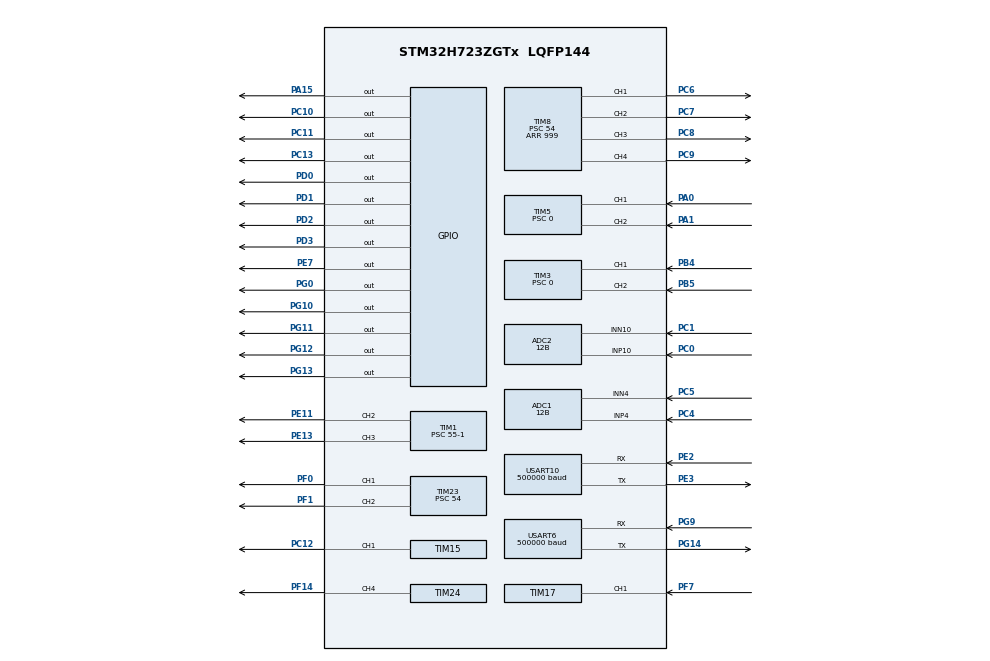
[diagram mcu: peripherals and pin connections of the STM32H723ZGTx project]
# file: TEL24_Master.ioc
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ADC1.Channel-0\#ChannelRegularConversion=ADC_CHANNEL_4
ADC1.ContinuousConvMode=ENABLE
ADC1.ConversionDataManagement=ADC_CONVERSIONDATA_DMA_CIRCULAR
ADC1.EOCSelection=ADC_EOC_SEQ_CONV
ADC1.NbrOfConversionFlag=1
ADC1.OffsetNumber-0\#ChannelRegularConversion=ADC_OFFSET_NONE
ADC1.OffsetSignedSaturation-0\#ChannelRegularConversion=DISABLE
ADC1.Overrun=ADC_OVR_DATA_OVERWRITTEN
ADC1.Rank-0\#ChannelRegularConversion=1
ADC1.Resolution=ADC_RESOLUTION_12B
ADC1.SamplingTime-0\#ChannelRegularConversion=ADC_SAMPLETIME_64CYCLES_5
ADC1.SingleDiff-0\#ChannelRegularConversion=ADC_DIFFERENTIAL_ENDED
ADC1.master=1
ADC2.Channel-0\#ChannelRegularConversion=ADC_CHANNEL_10
ADC2.ClockPrescaler=ADC_CLOCK_ASYNC_DIV1
ADC2.ContinuousConvMode=ENABLE
ADC2.ConversionDataManagement=ADC_CONVERSIONDATA_DMA_CIRCULAR
ADC2.DiscontinuousConvMode=DISABLE
ADC2.EOCSelection=ADC_EOC_SEQ_CONV
ADC2.ExternalTrigConv=ADC_SOFTWARE_START
ADC2.NbrOfConversion=1
ADC2.NbrOfConversionFlag=1
ADC2.Overrun=ADC_OVR_DATA_OVERWRITTEN
ADC2.Resolution=ADC_RESOLUTION_12B
ADC2.SamplingTime-0\#ChannelRegularConversion=ADC_SAMPLETIME_64CYCLES_5
ADC2.SingleDiff-0\#ChannelRegularConversion=ADC_DIFFERENTIAL_ENDED
Dma.ADC1.2.Direction=DMA_PERIPH_TO_MEMORY
Dma.ADC1.2.EventEnable=DISABLE
Dma.ADC1.2.FIFOMode=DMA_FIFOMODE_DISABLE
Dma.ADC1.2.Instance=DMA2_Stream1
Dma.ADC1.2.MemDataAlignment=DMA_MDATAALIGN_WORD
Dma.ADC1.2.MemInc=DMA_MINC_ENABLE
Dma.ADC1.2.Mode=DMA_CIRCULAR
Dma.ADC1.2.PeriphDataAlignment=DMA_PDATAALIGN_WORD
Dma.ADC1.2.PeriphInc=DMA_PINC_DISABLE
Dma.ADC1.2.Polarity=HAL_DMAMUX_REQ_GEN_RISING
Dma.ADC1.2.Priority=DMA_PRIORITY_LOW
Dma.ADC1.2.RequestNumber=1
Dma.ADC1.2.SignalID=NONE
Dma.ADC1.2.SyncEnable=DISABLE
Dma.ADC1.2.SyncPolarity=HAL_DMAMUX_SYNC_NO_EVENT
Dma.ADC1.2.SyncRequestNumber=1
Dma.ADC1.2.SyncSignalID=NONE
Dma.ADC2.1.Direction=DMA_PERIPH_TO_MEMORY
Dma.ADC2.1.EventEnable=DISABLE
Dma.ADC2.1.FIFOMode=DMA_FIFOMODE_DISABLE
Dma.ADC2.1.Instance=DMA2_Stream0
Dma.ADC2.1.MemDataAlignment=DMA_MDATAALIGN_WORD
Dma.ADC2.1.MemInc=DMA_MINC_ENABLE
Dma.ADC2.1.Mode=DMA_CIRCULAR
Dma.ADC2.1.PeriphDataAlignment=DMA_PDATAALIGN_WORD
Dma.ADC2.1.PeriphInc=DMA_PINC_DISABLE
Dma.ADC2.1.Polarity=HAL_DMAMUX_REQ_GEN_RISING
Dma.ADC2.1.Priority=DMA_PRIORITY_LOW
Dma.ADC2.1.RequestNumber=1
Dma.ADC2.1.SignalID=NONE
Dma.ADC2.1.SyncEnable=DISABLE
Dma.ADC2.1.SyncPolarity=HAL_DMAMUX_SYNC_NO_EVENT
Dma.ADC2.1.SyncRequestNumber=1
Dma.ADC2.1.SyncSignalID=NONE
Dma.Request0=TIM17_CH1
Dma.Request1=ADC2
Dma.Request2=ADC1
Dma.TIM17_CH1.0.Direction=DMA_PERIPH_TO_MEMORY
Dma.TIM17_CH1.0.EventEnable=DISABLE
Dma.TIM17_CH1.0.FIFOMode=DMA_FIFOMODE_DISABLE
Dma.TIM17_CH1.0.Instance=DMA1_Stream0
Dma.TIM17_CH1.0.MemDataAlignment=DMA_MDATAALIGN_WORD
Dma.TIM17_CH1.0.MemInc=DMA_MINC_ENABLE
Dma.TIM17_CH1.0.Mode=DMA_CIRCULAR
Dma.TIM17_CH1.0.PeriphDataAlignment=DMA_PDATAALIGN_WORD
Dma.TIM17_CH1.0.PeriphInc=DMA_PINC_DISABLE
Dma.TIM17_CH1.0.Polarity=HAL_DMAMUX_REQ_GEN_RISING
Dma.TIM17_CH1.0.Priority=DMA_PRIORITY_VERY_HIGH
Dma.TIM17_CH1.0.RequestNumber=1
Dma.TIM17_CH1.0.SignalID=NONE
Dma.TIM17_CH1.0.SyncEnable=DISABLE
Dma.TIM17_CH1.0.SyncPolarity=HAL_DMAMUX_SYNC_NO_EVENT
Dma.TIM17_CH1.0.SyncRequestNumber=1
Dma.TIM17_CH1.0.SyncSignalID=NONE
Mcu.Family=STM32H7
Mcu.Name=STM32H723ZGTx
Mcu.Package=LQFP144
NVIC.ADC_IRQn=true\:0\:0\:false\:false\:true\:true\:true\:true
NVIC.DMA1_Stream0_IRQn=true\:0\:0\:false\:false\:true\:false\:true\:true
NVIC.DMA2_Stream0_IRQn=true\:0\:0\:false\:false\:true\:false\:true\:true
NVIC.DMA2_Stream1_IRQn=true\:0\:0\:false\:false\:true\:false\:true\:true
NVIC.PriorityGroup=NVIC_PRIORITYGROUP_4
NVIC.RCC_IRQn=true\:0\:0\:false\:false\:true\:true\:false\:true
NVIC.TIM16_IRQn=true\:0\:0\:false\:false\:true\:true\:true\:true
NVIC.TIM6_DAC_IRQn=true\:0\:0\:false\:false\:true\:true\:true\:true
PA0.Signal=S_TIM5_CH1
PA1.Signal=S_TIM5_CH2
PA13(JTMS/SWDIO).Mode=Serial_Wire
PA13(JTMS/SWDIO).Signal=DEBUG_JTMS-SWDIO
PA14(JTCK/SWCLK).Mode=Serial_Wire
PA14(JTCK/SWCLK).Signal=DEBUG_JTCK-SWCLK
PA15(JTDI).Signal=GPIO_Output
PB4(NJTRST).Signal=S_TIM3_CH1
PB5.Signal=S_TIM3_CH2
PC0.Signal=ADCx_INP10
PC1.Signal=ADCx_INN10
PC10.Signal=GPIO_Output
PC11.Signal=GPIO_Output
PC12.Signal=S_TIM15_CH1
PC13.Signal=GPIO_Output
PC4.Signal=ADCx_INP4
PC5.Signal=ADCx_INN4
PC6.Signal=S_TIM8_CH1
PC7.Signal=S_TIM8_CH2
PC8.Signal=S_TIM8_CH3
PC9.Signal=S_TIM8_CH4
PD0.Signal=GPIO_Output
PD1.Signal=GPIO_Output
PD2.Signal=GPIO_Output
PD3.Signal=GPIO_Output
PE11.Signal=S_TIM1_CH2
PE13.Signal=S_TIM1_CH3
PE2.Mode=Asynchronous
PE2.Signal=USART10_RX
PE3.Mode=Asynchronous
PE3.Signal=USART10_TX
PE7.Signal=GPIO_Output
PF0.Mode=PWM Generation1 CH1
PF0.Signal=TIM23_CH1
PF1.Signal=S_TIM23_CH2
PF14.Signal=S_TIM24_CH4
PF7.Signal=S_TIM17_CH1
PG0.Signal=GPIO_Output
PG10.Signal=GPIO_Output
PG11.Signal=GPIO_Output
PG12.Signal=GPIO_Output
PG13.Signal=GPIO_Output
PG14.Mode=Asynchronous
PG14.Signal=USART6_TX
PG9.Mode=Asynchronous
PG9.Signal=USART6_RX
PH0-OSC_IN.Mode=HSE-External-Oscillator
PH0-OSC_IN.Signal=RCC_OSC_IN
PH1-OSC_OUT.Mode=HSE-External-Oscillator
PH1-OSC_OUT.Signal=RCC_OSC_OUT
ProjectManager.HeapSize=0x200
ProjectManager.StackSize=0x400
ProjectManager.TargetToolchain=STM32CubeIDE
RCC.ADCFreq_Value=129000000
RCC.APB1Freq_Value=137500000
RCC.APB2Freq_Value=137500000
RCC.APB3Freq_Value=137500000
RCC.APB4Freq_Value=137500000
RCC.CortexFreq_Value=550000000
RCC.D1PPRE=RCC_APB3_DIV2
RCC.D2PPRE1=RCC_APB1_DIV2
RCC.D2PPRE2=RCC_APB2_DIV2
RCC.D3PPRE=RCC_APB4_DIV2
RCC.DIVM1=4
RCC.DIVN1=34
RCC.DIVP1=1
RCC.HCLKFreq_Value=275000000
RCC.HPRE=RCC_HCLK_DIV2
RCC.HSE_VALUE=4000000
RCC.LSE_VALUE=32.77
RCC.PLL1_VCO_SEL-AdvancedSettings=RCC_PLL1VCOMEDIUM
RCC.PLL2FRACN=0
RCC.PLL2_VCO_SEL-AdvancedSettings=RCC_PLL2VCOWIDE
RCC.PLL3FRACN=0
RCC.PLL3_VCO_SEL-AdvancedSettings=RCC_PLL3VCOMEDIUM
RCC.PLLFRACN=3072
RCC.SYSCLKFreq_VALUE=550000000
RCC.SYSCLKSource=RCC_SYSCLKSOURCE_PLLCLK
RCC.USBFreq_Value=275000000
SH.ADCx_INN10.0=ADC2_INN10,IN10-Differential
SH.ADCx_INN4.0=ADC1_INN4,IN4-Differential
SH.ADCx_INP10.0=ADC2_INP10,IN10-Differential
SH.ADCx_INP4.0=ADC1_INP4,IN4-Differential
SH.S_TIM15_CH1.0=TIM15_CH1,PWM Generation1 CH1
SH.S_TIM17_CH1.0=TIM17_CH1,Input_Capture1_from_TI1
SH.S_TIM1_CH2.0=TIM1_CH2,PWM Generation2 CH2
SH.S_TIM1_CH3.0=TIM1_CH3,PWM Generation3 CH3
SH.S_TIM23_CH2.0=TIM23_CH2,PWM Generation2 CH2
SH.S_TIM24_CH4.0=TIM24_CH4,PWM Generation4 CH4
SH.S_TIM3_CH1.0=TIM3_CH1,Encoder_Interface
SH.S_TIM3_CH2.0=TIM3_CH2,Encoder_Interface
SH.S_TIM5_CH1.0=TIM5_CH1,Encoder_Interface
SH.S_TIM5_CH2.0=TIM5_CH2,Encoder_Interface
SH.S_TIM8_CH1.0=TIM8_CH1,PWM Generation1 CH1
SH.S_TIM8_CH2.0=TIM8_CH2,PWM Generation2 CH2
SH.S_TIM8_CH3.0=TIM8_CH3,PWM Generation3 CH3
SH.S_TIM8_CH4.0=TIM8_CH4,PWM Generation4 CH4
TIM1.Channel-PWM\ Generation2\ CH2=TIM_CHANNEL_2
TIM1.Channel-PWM\ Generation3\ CH3=TIM_CHANNEL_3
TIM1.Period=10500-1
TIM1.Prescaler=55-1
TIM15.Channel-PWM\ Generation1\ CH1=TIM_CHANNEL_1
TIM15.Period=999
TIM15.Prescaler=54
TIM16.Period=999
TIM16.Prescaler=274
TIM17.Channel=TIM_CHANNEL_1
TIM17.Prescaler=275-1
TIM23.Channel-PWM\ Generation1\ CH1=TIM_CHANNEL_1
TIM23.Channel-PWM\ Generation2\ CH2=TIM_CHANNEL_2
TIM23.Period=999
TIM23.Prescaler=54
TIM24.Channel-PWM\ Generation4\ CH4=TIM_CHANNEL_4
TIM24.Period=999
TIM24.Prescaler=54
TIM3.EncoderMode=TIM_ENCODERMODE_TI12
TIM3.Period=65535
TIM3.Prescaler=0
TIM4.Period=10000-1
TIM4.Prescaler=275-1
TIM5.EncoderMode=TIM_ENCODERMODE_TI12
TIM5.Period=65535
TIM5.Prescaler=0
TIM6.Period=500-1
TIM6.Prescaler=100-1
TIM8.Channel-PWM\ Generation1\ CH1=TIM_CHANNEL_1
TIM8.Channel-PWM\ Generation2\ CH2=TIM_CHANNEL_2
TIM8.Channel-PWM\ Generation3\ CH3=TIM_CHANNEL_3
TIM8.Channel-PWM\ Generation4\ CH4=TIM_CHANNEL_4
TIM8.Period=999
TIM8.Prescaler=54
USART10.BaudRate=500000
USART10.VirtualMode-Asynchronous=VM_ASYNC
USART6.BaudRate=500000
USART6.VirtualMode-Asynchronous=VM_ASYNC
VP_TIM15_VS_ClockSourceINT.Mode=Internal
VP_TIM16_VS_ClockSourceINT.Mode=Enable_Timer
VP_TIM17_VS_ClockSourceINT.Mode=Enable_Timer
VP_TIM23_VS_ClockSourceINT.Mode=Internal
VP_TIM24_VS_ClockSourceINT.Mode=Internal
VP_TIM4_VS_ClockSourceINT.Mode=Internal
VP_TIM6_VS_ClockSourceINT.Mode=Enable_Timer
board=custom

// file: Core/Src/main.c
/* USER CODE BEGIN Header */
/**
  ******************************************************************************
  * @file           : main.c
  * @brief          : Main program body
  ******************************************************************************
  * @attention
  *
  * Copyright (c) 2024 STMicroelectronics.
  * All rights reserved.
  *
  * This software is licensed under terms that can be found in the LICENSE file
  * in the root directory of this software component.
  * If no LICENSE file comes with this software, it is provided AS-IS.
  *
  ******************************************************************************
  */
/* USER CODE END Header */
#include "main.h"

/* USER CODE BEGIN Includes */
#include "mainpp.h"
/* USER CODE END Includes */

ADC_HandleTypeDef hadc1;
ADC_HandleTypeDef hadc2;
DMA_HandleTypeDef hdma_adc1;
DMA_HandleTypeDef hdma_adc2;

TIM_HandleTypeDef htim1;
TIM_HandleTypeDef htim3;
TIM_HandleTypeDef htim4;
TIM_HandleTypeDef htim5;
TIM_HandleTypeDef htim6;
TIM_HandleTypeDef htim8;
TIM_HandleTypeDef htim15;
TIM_HandleTypeDef htim16;
TIM_HandleTypeDef htim17;
TIM_HandleTypeDef htim23;
TIM_HandleTypeDef htim24;
DMA_HandleTypeDef hdma_tim17_ch1;

UART_HandleTypeDef huart6;
UART_HandleTypeDef huart10;

void SystemClock_Config(void);
void PeriphCommonClock_Config(void);
static void MX_GPIO_Init(void);
static void MX_DMA_Init(void);
static void MX_TIM5_Init(void);
static void MX_TIM23_Init(void);
static void MX_TIM24_Init(void);
static void MX_TIM8_Init(void);
static void MX_TIM15_Init(void);
static void MX_TIM3_Init(void);
static void MX_TIM17_Init(void);
static void MX_TIM16_Init(void);
static void MX_TIM6_Init(void);
static void MX_USART6_UART_Init(void);
static void MX_USART10_UART_Init(void);
static void MX_ADC2_Init(void);
static void MX_TIM1_Init(void);
static void MX_TIM4_Init(void);
static void MX_ADC1_Init(void);

int main(void)
{

  /* MCU Configuration--------------------------------------------------------*/

  /* Reset of all peripherals, Initializes the Flash interface and the Systick. */
  HAL_Init();

  /* Configure the system clock */
  SystemClock_Config();

/* Configure the peripherals common clocks */
  PeriphCommonClock_Config();

  /* Initialize all configured peripherals */
  MX_GPIO_Init();
  MX_DMA_Init();
  MX_TIM5_Init();
  MX_TIM23_Init();
  MX_TIM24_Init();
  MX_TIM8_Init();
  MX_TIM15_Init();
  MX_TIM3_Init();
  MX_TIM17_Init();
  MX_TIM16_Init();
  MX_TIM6_Init();
  MX_USART6_UART_Init();
  MX_USART10_UART_Init();
  MX_ADC2_Init();
  MX_TIM1_Init();
  MX_TIM4_Init();
  MX_ADC1_Init();
  /* USER CODE BEGIN 2 */
  main_function();
  /* USER CODE END 2 */

  /* Infinite loop */
  while (1)
  {

  }
}

void SystemClock_Config(void)
{
  RCC_OscInitTypeDef RCC_OscInitStruct = {0};
  RCC_ClkInitTypeDef RCC_ClkInitStruct = {0};

  /** Supply configuration update enable
  */
  HAL_PWREx_ConfigSupply(PWR_LDO_SUPPLY);

  /** Configure the main internal regulator output voltage
  */
  __HAL_PWR_VOLTAGESCALING_CONFIG(PWR_REGULATOR_VOLTAGE_SCALE0);

  while(!__HAL_PWR_GET_FLAG(PWR_FLAG_VOSRDY)) {}

  /** Initializes the RCC Oscillators according to the specified parameters
  * in the RCC_OscInitTypeDef structure.
  */
  RCC_OscInitStruct.OscillatorType = RCC_OSCILLATORTYPE_HSI;
  RCC_OscInitStruct.HSIState = RCC_HSI_DIV1;
  RCC_OscInitStruct.HSICalibrationValue = 64;
  RCC_OscInitStruct.PLL.PLLState = RCC_PLL_ON;
  RCC_OscInitStruct.PLL.PLLSource = RCC_PLLSOURCE_HSI;
  RCC_OscInitStruct.PLL.PLLM = 4;
  RCC_OscInitStruct.PLL.PLLN = 34;
  RCC_OscInitStruct.PLL.PLLP = 1;
  RCC_OscInitStruct.PLL.PLLQ = 2;
  RCC_OscInitStruct.PLL.PLLR = 2;
  RCC_OscInitStruct.PLL.PLLRGE = RCC_PLL1VCIRANGE_3;
  RCC_OscInitStruct.PLL.PLLVCOSEL = RCC_PLL1VCOWIDE;
  RCC_OscInitStruct.PLL.PLLFRACN = 3072;
  if (HAL_RCC_OscConfig(&RCC_OscInitStruct) != HAL_OK)
  {
    Error_Handler();
  }

  /** Initializes the CPU, AHB and APB buses clocks
  */
  RCC_ClkInitStruct.ClockType = RCC_CLOCKTYPE_HCLK|RCC_CLOCKTYPE_SYSCLK
                              |RCC_CLOCKTYPE_PCLK1|RCC_CLOCKTYPE_PCLK2
                              |RCC_CLOCKTYPE_D3PCLK1|RCC_CLOCKTYPE_D1PCLK1;
  RCC_ClkInitStruct.SYSCLKSource = RCC_SYSCLKSOURCE_PLLCLK;
  RCC_ClkInitStruct.SYSCLKDivider = RCC_SYSCLK_DIV1;
  RCC_ClkInitStruct.AHBCLKDivider = RCC_HCLK_DIV2;
  RCC_ClkInitStruct.APB3CLKDivider = RCC_APB3_DIV2;
  RCC_ClkInitStruct.APB1CLKDivider = RCC_APB1_DIV2;
  RCC_ClkInitStruct.APB2CLKDivider = RCC_APB2_DIV2;
  RCC_ClkInitStruct.APB4CLKDivider = RCC_APB4_DIV2;

  if (HAL_RCC_ClockConfig(&RCC_ClkInitStruct, FLASH_LATENCY_3) != HAL_OK)
  {
    Error_Handler();
  }
}

void PeriphCommonClock_Config(void)
{
  RCC_PeriphCLKInitTypeDef PeriphClkInitStruct = {0};

  /** Initializes the peripherals clock
  */
  PeriphClkInitStruct.PeriphClockSelection = RCC_PERIPHCLK_ADC;
  PeriphClkInitStruct.PLL2.PLL2M = 32;
  PeriphClkInitStruct.PLL2.PLL2N = 129;
  PeriphClkInitStruct.PLL2.PLL2P = 2;
  PeriphClkInitStruct.PLL2.PLL2Q = 2;
  PeriphClkInitStruct.PLL2.PLL2R = 2;
  PeriphClkInitStruct.PLL2.PLL2RGE = RCC_PLL2VCIRANGE_1;
  PeriphClkInitStruct.PLL2.PLL2VCOSEL = RCC_PLL2VCOWIDE;
  PeriphClkInitStruct.PLL2.PLL2FRACN = 0;
  PeriphClkInitStruct.AdcClockSelection = RCC_ADCCLKSOURCE_PLL2;
  if (HAL_RCCEx_PeriphCLKConfig(&PeriphClkInitStruct) != HAL_OK)
  {
    Error_Handler();
  }
}

static void MX_ADC1_Init(void)
{

  ADC_MultiModeTypeDef multimode = {0};
  ADC_ChannelConfTypeDef sConfig = {0};

  /** Common config
  */
  hadc1.Instance = ADC1;
  hadc1.Init.ClockPrescaler = ADC_CLOCK_ASYNC_DIV1;
  hadc1.Init.Resolution = ADC_RESOLUTION_12B;
  hadc1.Init.ScanConvMode = ADC_SCAN_DISABLE;
  hadc1.Init.EOCSelection = ADC_EOC_SEQ_CONV;
  hadc1.Init.LowPowerAutoWait = DISABLE;
  hadc1.Init.ContinuousConvMode = ENABLE;
  hadc1.Init.NbrOfConversion = 1;
  hadc1.Init.DiscontinuousConvMode = DISABLE;
  hadc1.Init.ExternalTrigConv = ADC_SOFTWARE_START;
  hadc1.Init.ExternalTrigConvEdge = ADC_EXTERNALTRIGCONVEDGE_NONE;
  hadc1.Init.ConversionDataManagement = ADC_CONVERSIONDATA_DMA_CIRCULAR;
  hadc1.Init.Overrun = ADC_OVR_DATA_OVERWRITTEN;
  hadc1.Init.LeftBitShift = ADC_LEFTBITSHIFT_NONE;
  hadc1.Init.OversamplingMode = DISABLE;
  if (HAL_ADC_Init(&hadc1) != HAL_OK)
  {
    Error_Handler();
  }

  /** Configure the ADC multi-mode
  */
  multimode.Mode = ADC_MODE_INDEPENDENT;
  if (HAL_ADCEx_MultiModeConfigChannel(&hadc1, &multimode) != HAL_OK)
  {
    Error_Handler();
  }

  /** Configure Regular Channel
  */
  sConfig.Channel = ADC_CHANNEL_4;
  sConfig.Rank = ADC_REGULAR_RANK_1;
  sConfig.SamplingTime = ADC_SAMPLETIME_64CYCLES_5;
  sConfig.SingleDiff = ADC_DIFFERENTIAL_ENDED;
  sConfig.OffsetNumber = ADC_OFFSET_NONE;
  sConfig.Offset = 0;
  sConfig.OffsetSignedSaturation = DISABLE;
  if (HAL_ADC_ConfigChannel(&hadc1, &sConfig) != HAL_OK)
  {
    Error_Handler();
  }

}

static void MX_ADC2_Init(void)
{

  ADC_ChannelConfTypeDef sConfig = {0};

  /** Common config
  */
  hadc2.Instance = ADC2;
  hadc2.Init.ClockPrescaler = ADC_CLOCK_ASYNC_DIV1;
  hadc2.Init.Resolution = ADC_RESOLUTION_12B;
  hadc2.Init.ScanConvMode = ADC_SCAN_DISABLE;
  hadc2.Init.EOCSelection = ADC_EOC_SEQ_CONV;
  hadc2.Init.LowPowerAutoWait = DISABLE;
  hadc2.Init.ContinuousConvMode = ENABLE;
  hadc2.Init.NbrOfConversion = 1;
  hadc2.Init.DiscontinuousConvMode = DISABLE;
  hadc2.Init.ExternalTrigConv = ADC_SOFTWARE_START;
  hadc2.Init.ExternalTrigConvEdge = ADC_EXTERNALTRIGCONVEDGE_NONE;
  hadc2.Init.ConversionDataManagement = ADC_CONVERSIONDATA_DMA_CIRCULAR;
  hadc2.Init.Overrun = ADC_OVR_DATA_OVERWRITTEN;
  hadc2.Init.LeftBitShift = ADC_LEFTBITSHIFT_NONE;
  hadc2.Init.OversamplingMode = DISABLE;
  if (HAL_ADC_Init(&hadc2) != HAL_OK)
  {
    Error_Handler();
  }

  /** Configure Regular Channel
  */
  sConfig.Channel = ADC_CHANNEL_10;
  sConfig.Rank = ADC_REGULAR_RANK_1;
  sConfig.SamplingTime = ADC_SAMPLETIME_64CYCLES_5;
  sConfig.SingleDiff = ADC_DIFFERENTIAL_ENDED;
  sConfig.OffsetNumber = ADC_OFFSET_NONE;
  sConfig.Offset = 0;
  if (HAL_ADC_ConfigChannel(&hadc2, &sConfig) != HAL_OK)
  {
    Error_Handler();
  }

}

static void MX_TIM1_Init(void)
{

  TIM_MasterConfigTypeDef sMasterConfig = {0};
  TIM_OC_InitTypeDef sConfigOC = {0};
  TIM_BreakDeadTimeConfigTypeDef sBreakDeadTimeConfig = {0};

  htim1.Instance = TIM1;
  htim1.Init.Prescaler = 55-1;
  htim1.Init.CounterMode = TIM_COUNTERMODE_UP;
  htim1.Init.Period = 10500-1;
  htim1.Init.ClockDivision = TIM_CLOCKDIVISION_DIV1;
  htim1.Init.RepetitionCounter = 0;
  htim1.Init.AutoReloadPreload = TIM_AUTORELOAD_PRELOAD_DISABLE;
  if (HAL_TIM_PWM_Init(&htim1) != HAL_OK)
  {
    Error_Handler();
  }
  sMasterConfig.MasterOutputTrigger = TIM_TRGO_RESET;
  sMasterConfig.MasterOutputTrigger2 = TIM_TRGO2_RESET;
  sMasterConfig.MasterSlaveMode = TIM_MASTERSLAVEMODE_DISABLE;
  if (HAL_TIMEx_MasterConfigSynchronization(&htim1, &sMasterConfig) != HAL_OK)
  {
    Error_Handler();
  }
  sConfigOC.OCMode = TIM_OCMODE_PWM1;
  sConfigOC.Pulse = 0;
  sConfigOC.OCPolarity = TIM_OCPOLARITY_HIGH;
  sConfigOC.OCNPolarity = TIM_OCNPOLARITY_HIGH;
  sConfigOC.OCFastMode = TIM_OCFAST_DISABLE;
  sConfigOC.OCIdleState = TIM_OCIDLESTATE_RESET;
  sConfigOC.OCNIdleState = TIM_OCNIDLESTATE_RESET;
  if (HAL_TIM_PWM_ConfigChannel(&htim1, &sConfigOC, TIM_CHANNEL_2) != HAL_OK)
  {
    Error_Handler();
  }
  if (HAL_TIM_PWM_ConfigChannel(&htim1, &sConfigOC, TIM_CHANNEL_3) != HAL_OK)
  {
    Error_Handler();
  }
  sBreakDeadTimeConfig.OffStateRunMode = TIM_OSSR_DISABLE;
  sBreakDeadTimeConfig.OffStateIDLEMode = TIM_OSSI_DISABLE;
  sBreakDeadTimeConfig.LockLevel = TIM_LOCKLEVEL_OFF;
  sBreakDeadTimeConfig.DeadTime = 0;
  sBreakDeadTimeConfig.BreakState = TIM_BREAK_DISABLE;
  sBreakDeadTimeConfig.BreakPolarity = TIM_BREAKPOLARITY_HIGH;
  sBreakDeadTimeConfig.BreakFilter = 0;
  sBreakDeadTimeConfig.Break2State = TIM_BREAK2_DISABLE;
  sBreakDeadTimeConfig.Break2Polarity = TIM_BREAK2POLARITY_HIGH;
  sBreakDeadTimeConfig.Break2Filter = 0;
  sBreakDeadTimeConfig.AutomaticOutput = TIM_AUTOMATICOUTPUT_DISABLE;
  if (HAL_TIMEx_ConfigBreakDeadTime(&htim1, &sBreakDeadTimeConfig) != HAL_OK)
  {
    Error_Handler();
  }
  HAL_TIM_MspPostInit(&htim1);

}

static void MX_TIM3_Init(void)
{

  TIM_Encoder_InitTypeDef sConfig = {0};
  TIM_MasterConfigTypeDef sMasterConfig = {0};

  htim3.Instance = TIM3;
  htim3.Init.Prescaler = 0;
  htim3.Init.CounterMode = TIM_COUNTERMODE_UP;
  htim3.Init.Period = 65535;
  htim3.Init.ClockDivision = TIM_CLOCKDIVISION_DIV1;
  htim3.Init.AutoReloadPreload = TIM_AUTORELOAD_PRELOAD_DISABLE;
  sConfig.EncoderMode = TIM_ENCODERMODE_TI12;
  sConfig.IC1Polarity = TIM_ICPOLARITY_RISING;
  sConfig.IC1Selection = TIM_ICSELECTION_DIRECTTI;
  sConfig.IC1Prescaler = TIM_ICPSC_DIV1;
  sConfig.IC1Filter = 0;
  sConfig.IC2Polarity = TIM_ICPOLARITY_RISING;
  sConfig.IC2Selection = TIM_ICSELECTION_DIRECTTI;
  sConfig.IC2Prescaler = TIM_ICPSC_DIV1;
  sConfig.IC2Filter = 0;
  if (HAL_TIM_Encoder_Init(&htim3, &sConfig) != HAL_OK)
  {
    Error_Handler();
  }
  sMasterConfig.MasterOutputTrigger = TIM_TRGO_RESET;
  sMasterConfig.MasterSlaveMode = TIM_MASTERSLAVEMODE_DISABLE;
  if (HAL_TIMEx_MasterConfigSynchronization(&htim3, &sMasterConfig) != HAL_OK)
  {
    Error_Handler();
  }

}

static void MX_TIM4_Init(void)
{

  TIM_ClockConfigTypeDef sClockSourceConfig = {0};
  TIM_MasterConfigTypeDef sMasterConfig = {0};

  htim4.Instance = TIM4;
  htim4.Init.Prescaler = 275-1;
  htim4.Init.CounterMode = TIM_COUNTERMODE_UP;
  htim4.Init.Period = 10000-1;
  htim4.Init.ClockDivision = TIM_CLOCKDIVISION_DIV1;
  htim4.Init.AutoReloadPreload = TIM_AUTORELOAD_PRELOAD_DISABLE;
  if (HAL_TIM_Base_Init(&htim4) != HAL_OK)
  {
    Error_Handler();
  }
  sClockSourceConfig.ClockSource = TIM_CLOCKSOURCE_INTERNAL;
  if (HAL_TIM_ConfigClockSource(&htim4, &sClockSourceConfig) != HAL_OK)
  {
    Error_Handler();
  }
  sMasterConfig.MasterOutputTrigger = TIM_TRGO_RESET;
  sMasterConfig.MasterSlaveMode = TIM_MASTERSLAVEMODE_DISABLE;
  if (HAL_TIMEx_MasterConfigSynchronization(&htim4, &sMasterConfig) != HAL_OK)
  {
    Error_Handler();
  }

}

static void MX_TIM5_Init(void)
{

  TIM_Encoder_InitTypeDef sConfig = {0};
  TIM_MasterConfigTypeDef sMasterConfig = {0};

  htim5.Instance = TIM5;
  htim5.Init.Prescaler = 0;
  htim5.Init.CounterMode = TIM_COUNTERMODE_UP;
  htim5.Init.Period = 65535;
  htim5.Init.ClockDivision = TIM_CLOCKDIVISION_DIV1;
  htim5.Init.AutoReloadPreload = TIM_AUTORELOAD_PRELOAD_DISABLE;
  sConfig.EncoderMode = TIM_ENCODERMODE_TI12;
  sConfig.IC1Polarity = TIM_ICPOLARITY_RISING;
  sConfig.IC1Selection = TIM_ICSELECTION_DIRECTTI;
  sConfig.IC1Prescaler = TIM_ICPSC_DIV1;
  sConfig.IC1Filter = 0;
  sConfig.IC2Polarity = TIM_ICPOLARITY_RISING;
  sConfig.IC2Selection = TIM_ICSELECTION_DIRECTTI;
  sConfig.IC2Prescaler = TIM_ICPSC_DIV1;
  sConfig.IC2Filter = 0;
  if (HAL_TIM_Encoder_Init(&htim5, &sConfig) != HAL_OK)
  {
    Error_Handler();
  }
  sMasterConfig.MasterOutputTrigger = TIM_TRGO_RESET;
  sMasterConfig.MasterSlaveMode = TIM_MASTERSLAVEMODE_DISABLE;
  if (HAL_TIMEx_MasterConfigSynchronization(&htim5, &sMasterConfig) != HAL_OK)
  {
    Error_Handler();
  }

}

static void MX_TIM6_Init(void)
{

  TIM_MasterConfigTypeDef sMasterConfig = {0};

  htim6.Instance = TIM6;
  htim6.Init.Prescaler = 100-1;
  htim6.Init.CounterMode = TIM_COUNTERMODE_UP;
  htim6.Init.Period = 500-1;
  htim6.Init.AutoReloadPreload = TIM_AUTORELOAD_PRELOAD_DISABLE;
  if (HAL_TIM_Base_Init(&htim6) != HAL_OK)
  {
    Error_Handler();
  }
  sMasterConfig.MasterOutputTrigger = TIM_TRGO_RESET;
  sMasterConfig.MasterSlaveMode = TIM_MASTERSLAVEMODE_DISABLE;
  if (HAL_TIMEx_MasterConfigSynchronization(&htim6, &sMasterConfig) != HAL_OK)
  {
    Error_Handler();
  }

}

static void MX_TIM8_Init(void)
{

  TIM_MasterConfigTypeDef sMasterConfig = {0};
  TIM_OC_InitTypeDef sConfigOC = {0};
  TIM_BreakDeadTimeConfigTypeDef sBreakDeadTimeConfig = {0};

  htim8.Instance = TIM8;
  htim8.Init.Prescaler = 54;
  htim8.Init.CounterMode = TIM_COUNTERMODE_UP;
  htim8.Init.Period = 999;
  htim8.Init.ClockDivision = TIM_CLOCKDIVISION_DIV1;
  htim8.Init.RepetitionCounter = 0;
  htim8.Init.AutoReloadPreload = TIM_AUTORELOAD_PRELOAD_DISABLE;
  if (HAL_TIM_PWM_Init(&htim8) != HAL_OK)
  {
    Error_Handler();
  }
  sMasterConfig.MasterOutputTrigger = TIM_TRGO_RESET;
  sMasterConfig.MasterOutputTrigger2 = TIM_TRGO2_RESET;
  sMasterConfig.MasterSlaveMode = TIM_MASTERSLAVEMODE_DISABLE;
  if (HAL_TIMEx_MasterConfigSynchronization(&htim8, &sMasterConfig) != HAL_OK)
  {
    Error_Handler();
  }
  sConfigOC.OCMode = TIM_OCMODE_PWM1;
  sConfigOC.Pulse = 0;
  sConfigOC.OCPolarity = TIM_OCPOLARITY_HIGH;
  sConfigOC.OCNPolarity = TIM_OCNPOLARITY_HIGH;
  sConfigOC.OCFastMode = TIM_OCFAST_DISABLE;
  sConfigOC.OCIdleState = TIM_OCIDLESTATE_RESET;
  sConfigOC.OCNIdleState = TIM_OCNIDLESTATE_RESET;
  if (HAL_TIM_PWM_ConfigChannel(&htim8, &sConfigOC, TIM_CHANNEL_1) != HAL_OK)
  {
    Error_Handler();
  }
  if (HAL_TIM_PWM_ConfigChannel(&htim8, &sConfigOC, TIM_CHANNEL_2) != HAL_OK)
  {
    Error_Handler();
  }
  if (HAL_TIM_PWM_ConfigChannel(&htim8, &sConfigOC, TIM_CHANNEL_3) != HAL_OK)
  {
    Error_Handler();
  }
  if (HAL_TIM_PWM_ConfigChannel(&htim8, &sConfigOC, TIM_CHANNEL_4) != HAL_OK)
  {
    Error_Handler();
  }
  sBreakDeadTimeConfig.OffStateRunMode = TIM_OSSR_DISABLE;
  sBreakDeadTimeConfig.OffStateIDLEMode = TIM_OSSI_DISABLE;
  sBreakDeadTimeConfig.LockLevel = TIM_LOCKLEVEL_OFF;
  sBreakDeadTimeConfig.DeadTime = 0;
  sBreakDeadTimeConfig.BreakState = TIM_BREAK_DISABLE;
  sBreakDeadTimeConfig.BreakPolarity = TIM_BREAKPOLARITY_HIGH;
  sBreakDeadTimeConfig.BreakFilter = 0;
  sBreakDeadTimeConfig.Break2State = TIM_BREAK2_DISABLE;
  sBreakDeadTimeConfig.Break2Polarity = TIM_BREAK2POLARITY_HIGH;
  sBreakDeadTimeConfig.Break2Filter = 0;
  sBreakDeadTimeConfig.AutomaticOutput = TIM_AUTOMATICOUTPUT_DISABLE;
  if (HAL_TIMEx_ConfigBreakDeadTime(&htim8, &sBreakDeadTimeConfig) != HAL_OK)
  {
    Error_Handler();
  }
  HAL_TIM_MspPostInit(&htim8);

}

static void MX_TIM15_Init(void)
{

  TIM_ClockConfigTypeDef sClockSourceConfig = {0};
  TIM_MasterConfigTypeDef sMasterConfig = {0};
  TIM_OC_InitTypeDef sConfigOC = {0};
  TIM_BreakDeadTimeConfigTypeDef sBreakDeadTimeConfig = {0};

  htim15.Instance = TIM15;
  htim15.Init.Prescaler = 54;
  htim15.Init.CounterMode = TIM_COUNTERMODE_UP;
  htim15.Init.Period = 999;
  htim15.Init.ClockDivision = TIM_CLOCKDIVISION_DIV1;
  htim15.Init.RepetitionCounter = 0;
  htim15.Init.AutoReloadPreload = TIM_AUTORELOAD_PRELOAD_DISABLE;
  if (HAL_TIM_Base_Init(&htim15) != HAL_OK)
  {
    Error_Handler();
  }
  sClockSourceConfig.ClockSource = TIM_CLOCKSOURCE_INTERNAL;
  if (HAL_TIM_ConfigClockSource(&htim15, &sClockSourceConfig) != HAL_OK)
  {
    Error_Handler();
  }
  if (HAL_TIM_PWM_Init(&htim15) != HAL_OK)
  {
    Error_Handler();
  }
  sMasterConfig.MasterOutputTrigger = TIM_TRGO_RESET;
  sMasterConfig.MasterSlaveMode = TIM_MASTERSLAVEMODE_DISABLE;
  if (HAL_TIMEx_MasterConfigSynchronization(&htim15, &sMasterConfig) != HAL_OK)
  {
    Error_Handler();
  }
  sConfigOC.OCMode = TIM_OCMODE_PWM1;
  sConfigOC.Pulse = 0;
  sConfigOC.OCPolarity = TIM_OCPOLARITY_HIGH;
  sConfigOC.OCNPolarity = TIM_OCNPOLARITY_HIGH;
  sConfigOC.OCFastMode = TIM_OCFAST_DISABLE;
  sConfigOC.OCIdleState = TIM_OCIDLESTATE_RESET;
  sConfigOC.OCNIdleState = TIM_OCNIDLESTATE_RESET;
  if (HAL_TIM_PWM_ConfigChannel(&htim15, &sConfigOC, TIM_CHANNEL_1) != HAL_OK)
  {
    Error_Handler();
  }
  sBreakDeadTimeConfig.OffStateRunMode = TIM_OSSR_DISABLE;
  sBreakDeadTimeConfig.OffStateIDLEMode = TIM_OSSI_DISABLE;
  sBreakDeadTimeConfig.LockLevel = TIM_LOCKLEVEL_OFF;
  sBreakDeadTimeConfig.DeadTime = 0;
  sBreakDeadTimeConfig.BreakState = TIM_BREAK_DISABLE;
  sBreakDeadTimeConfig.BreakPolarity = TIM_BREAKPOLARITY_HIGH;
  sBreakDeadTimeConfig.BreakFilter = 0;
  sBreakDeadTimeConfig.AutomaticOutput = TIM_AUTOMATICOUTPUT_DISABLE;
  if (HAL_TIMEx_ConfigBreakDeadTime(&htim15, &sBreakDeadTimeConfig) != HAL_OK)
  {
    Error_Handler();
  }
  HAL_TIM_MspPostInit(&htim15);

}

static void MX_TIM16_Init(void)
{

  htim16.Instance = TIM16;
  htim16.Init.Prescaler = 274;
  htim16.Init.CounterMode = TIM_COUNTERMODE_UP;
  htim16.Init.Period = 999;
  htim16.Init.ClockDivision = TIM_CLOCKDIVISION_DIV1;
  htim16.Init.RepetitionCounter = 0;
  htim16.Init.AutoReloadPreload = TIM_AUTORELOAD_PRELOAD_DISABLE;
  if (HAL_TIM_Base_Init(&htim16) != HAL_OK)
  {
    Error_Handler();
  }

}

static void MX_TIM17_Init(void)
{

  TIM_IC_InitTypeDef sConfigIC = {0};

  htim17.Instance = TIM17;
  htim17.Init.Prescaler = 275-1;
  htim17.Init.CounterMode = TIM_COUNTERMODE_UP;
  htim17.Init.Period = 65535;
  htim17.Init.ClockDivision = TIM_CLOCKDIVISION_DIV1;
  htim17.Init.RepetitionCounter = 0;
  htim17.Init.AutoReloadPreload = TIM_AUTORELOAD_PRELOAD_DISABLE;
  if (HAL_TIM_Base_Init(&htim17) != HAL_OK)
  {
    Error_Handler();
  }
  if (HAL_TIM_IC_Init(&htim17) != HAL_OK)
  {
    Error_Handler();
  }
  sConfigIC.ICPolarity = TIM_INPUTCHANNELPOLARITY_RISING;
  sConfigIC.ICSelection = TIM_ICSELECTION_DIRECTTI;
  sConfigIC.ICPrescaler = TIM_ICPSC_DIV1;
  sConfigIC.ICFilter = 0;
  if (HAL_TIM_IC_ConfigChannel(&htim17, &sConfigIC, TIM_CHANNEL_1) != HAL_OK)
  {
    Error_Handler();
  }

}

static void MX_TIM23_Init(void)
{

  TIM_ClockConfigTypeDef sClockSourceConfig = {0};
  TIM_MasterConfigTypeDef sMasterConfig = {0};
  TIM_OC_InitTypeDef sConfigOC = {0};

  htim23.Instance = TIM23;
  htim23.Init.Prescaler = 54;
  htim23.Init.CounterMode = TIM_COUNTERMODE_UP;
  htim23.Init.Period = 999;
  htim23.Init.ClockDivision = TIM_CLOCKDIVISION_DIV1;
  htim23.Init.AutoReloadPreload = TIM_AUTORELOAD_PRELOAD_DISABLE;
  if (HAL_TIM_Base_Init(&htim23) != HAL_OK)
  {
    Error_Handler();
  }
  sClockSourceConfig.ClockSource = TIM_CLOCKSOURCE_INTERNAL;
  if (HAL_TIM_ConfigClockSource(&htim23, &sClockSourceConfig) != HAL_OK)
  {
    Error_Handler();
  }
  if (HAL_TIM_PWM_Init(&htim23) != HAL_OK)
  {
    Error_Handler();
  }
  sMasterConfig.MasterOutputTrigger = TIM_TRGO_RESET;
  sMasterConfig.MasterSlaveMode = TIM_MASTERSLAVEMODE_DISABLE;
  if (HAL_TIMEx_MasterConfigSynchronization(&htim23, &sMasterConfig) != HAL_OK)
  {
    Error_Handler();
  }
  sConfigOC.OCMode = TIM_OCMODE_PWM1;
  sConfigOC.Pulse = 0;
  sConfigOC.OCPolarity = TIM_OCPOLARITY_HIGH;
  sConfigOC.OCFastMode = TIM_OCFAST_DISABLE;
  if (HAL_TIM_PWM_ConfigChannel(&htim23, &sConfigOC, TIM_CHANNEL_1) != HAL_OK)
  {
    Error_Handler();
  }
  if (HAL_TIM_PWM_ConfigChannel(&htim23, &sConfigOC, TIM_CHANNEL_2) != HAL_OK)
  {
    Error_Handler();
  }
  HAL_TIM_MspPostInit(&htim23);

}

static void MX_TIM24_Init(void)
{

  TIM_ClockConfigTypeDef sClockSourceConfig = {0};
  TIM_MasterConfigTypeDef sMasterConfig = {0};
  TIM_OC_InitTypeDef sConfigOC = {0};

  htim24.Instance = TIM24;
  htim24.Init.Prescaler = 54;
  htim24.Init.CounterMode = TIM_COUNTERMODE_UP;
  htim24.Init.Period = 999;
  htim24.Init.ClockDivision = TIM_CLOCKDIVISION_DIV1;
  htim24.Init.AutoReloadPreload = TIM_AUTORELOAD_PRELOAD_DISABLE;
  if (HAL_TIM_Base_Init(&htim24) != HAL_OK)
  {
    Error_Handler();
  }
  sClockSourceConfig.ClockSource = TIM_CLOCKSOURCE_INTERNAL;
  if (HAL_TIM_ConfigClockSource(&htim24, &sClockSourceConfig) != HAL_OK)
  {
    Error_Handler();
  }
  if (HAL_TIM_PWM_Init(&htim24) != HAL_OK)
  {
    Error_Handler();
  }
  sMasterConfig.MasterOutputTrigger = TIM_TRGO_RESET;
  sMasterConfig.MasterSlaveMode = TIM_MASTERSLAVEMODE_DISABLE;
  if (HAL_TIMEx_MasterConfigSynchronization(&htim24, &sMasterConfig) != HAL_OK)
  {
    Error_Handler();
  }
  sConfigOC.OCMode = TIM_OCMODE_PWM1;
  sConfigOC.Pulse = 0;
  sConfigOC.OCPolarity = TIM_OCPOLARITY_HIGH;
  sConfigOC.OCFastMode = TIM_OCFAST_DISABLE;
  if (HAL_TIM_PWM_ConfigChannel(&htim24, &sConfigOC, TIM_CHANNEL_4) != HAL_OK)
  {
    Error_Handler();
  }
  HAL_TIM_MspPostInit(&htim24);

}

static void MX_USART6_UART_Init(void)
{

  huart6.Instance = USART6;
  huart6.Init.BaudRate = 500000;
  huart6.Init.WordLength = UART_WORDLENGTH_8B;
  huart6.Init.StopBits = UART_STOPBITS_1;
  huart6.Init.Parity = UART_PARITY_NONE;
  huart6.Init.Mode = UART_MODE_TX_RX;
  huart6.Init.HwFlowCtl = UART_HWCONTROL_NONE;
  huart6.Init.OverSampling = UART_OVERSAMPLING_16;
  huart6.Init.OneBitSampling = UART_ONE_BIT_SAMPLE_DISABLE;
  huart6.Init.ClockPrescaler = UART_PRESCALER_DIV1;
  huart6.AdvancedInit.AdvFeatureInit = UART_ADVFEATURE_NO_INIT;
  if (HAL_UART_Init(&huart6) != HAL_OK)
  {
    Error_Handler();
  }
  if (HAL_UARTEx_SetTxFifoThreshold(&huart6, UART_TXFIFO_THRESHOLD_1_8) != HAL_OK)
  {
    Error_Handler();
  }
  if (HAL_UARTEx_SetRxFifoThreshold(&huart6, UART_RXFIFO_THRESHOLD_1_8) != HAL_OK)
  {
    Error_Handler();
  }
  if (HAL_UARTEx_DisableFifoMode(&huart6) != HAL_OK)
  {
    Error_Handler();
  }

}

static void MX_USART10_UART_Init(void)
{

  huart10.Instance = USART10;
  huart10.Init.BaudRate = 500000;
  huart10.Init.WordLength = UART_WORDLENGTH_8B;
  huart10.Init.StopBits = UART_STOPBITS_1;
  huart10.Init.Parity = UART_PARITY_NONE;
  huart10.Init.Mode = UART_MODE_TX_RX;
  huart10.Init.HwFlowCtl = UART_HWCONTROL_NONE;
  huart10.Init.OverSampling = UART_OVERSAMPLING_16;
  huart10.Init.OneBitSampling = UART_ONE_BIT_SAMPLE_DISABLE;
  huart10.Init.ClockPrescaler = UART_PRESCALER_DIV1;
  huart10.AdvancedInit.AdvFeatureInit = UART_ADVFEATURE_NO_INIT;
  if (HAL_UART_Init(&huart10) != HAL_OK)
  {
    Error_Handler();
  }
  if (HAL_UARTEx_SetTxFifoThreshold(&huart10, UART_TXFIFO_THRESHOLD_1_8) != HAL_OK)
  {
    Error_Handler();
  }
  if (HAL_UARTEx_SetRxFifoThreshold(&huart10, UART_RXFIFO_THRESHOLD_1_8) != HAL_OK)
  {
    Error_Handler();
  }
  if (HAL_UARTEx_DisableFifoMode(&huart10) != HAL_OK)
  {
    Error_Handler();
  }

}

static void MX_DMA_Init(void)
{

  /* DMA controller clock enable */
  __HAL_RCC_DMA1_CLK_ENABLE();
  __HAL_RCC_DMA2_CLK_ENABLE();

  /* DMA interrupt init */
  /* DMA1_Stream0_IRQn interrupt configuration */
  HAL_NVIC_SetPriority(DMA1_Stream0_IRQn, 0, 0);
  HAL_NVIC_EnableIRQ(DMA1_Stream0_IRQn);
  /* DMA2_Stream0_IRQn interrupt configuration */
  HAL_NVIC_SetPriority(DMA2_Stream0_IRQn, 0, 0);
  HAL_NVIC_EnableIRQ(DMA2_Stream0_IRQn);
  /* DMA2_Stream1_IRQn interrupt configuration */
  HAL_NVIC_SetPriority(DMA2_Stream1_IRQn, 0, 0);
  HAL_NVIC_EnableIRQ(DMA2_Stream1_IRQn);

}

static void MX_GPIO_Init(void)
{
  GPIO_InitTypeDef GPIO_InitStruct = {0};

  /* GPIO Ports Clock Enable */
  __HAL_RCC_GPIOE_CLK_ENABLE();
  __HAL_RCC_GPIOC_CLK_ENABLE();
  __HAL_RCC_GPIOF_CLK_ENABLE();
  __HAL_RCC_GPIOH_CLK_ENABLE();
  __HAL_RCC_GPIOA_CLK_ENABLE();
  __HAL_RCC_GPIOG_CLK_ENABLE();
  __HAL_RCC_GPIOD_CLK_ENABLE();
  __HAL_RCC_GPIOB_CLK_ENABLE();

  /*Configure GPIO pin Output Level */
  HAL_GPIO_WritePin(GPIOC, GPIO_PIN_13|GPIO_PIN_10|GPIO_PIN_11, GPIO_PIN_RESET);

  /*Configure GPIO pin Output Level */
  HAL_GPIO_WritePin(GPIOG, GPIO_PIN_0|GPIO_PIN_10|GPIO_PIN_11|GPIO_PIN_12
                          |GPIO_PIN_13, GPIO_PIN_RESET);

  /*Configure GPIO pin Output Level */
  HAL_GPIO_WritePin(GPIOE, GPIO_PIN_7, GPIO_PIN_RESET);

  /*Configure GPIO pin Output Level */
  HAL_GPIO_WritePin(GPIOA, GPIO_PIN_15, GPIO_PIN_RESET);

  /*Configure GPIO pin Output Level */
  HAL_GPIO_WritePin(GPIOD, GPIO_PIN_0|GPIO_PIN_1|GPIO_PIN_2|GPIO_PIN_3, GPIO_PIN_RESET);

  /*Configure GPIO pins : PC13 PC10 PC11 */
  GPIO_InitStruct.Pin = GPIO_PIN_13|GPIO_PIN_10|GPIO_PIN_11;
  GPIO_InitStruct.Mode = GPIO_MODE_OUTPUT_PP;
  GPIO_InitStruct.Pull = GPIO_NOPULL;
  GPIO_InitStruct.Speed = GPIO_SPEED_FREQ_LOW;
  HAL_GPIO_Init(GPIOC, &GPIO_InitStruct);

  /*Configure GPIO pins : PG0 PG10 PG11 PG12
                           PG13 */
  GPIO_InitStruct.Pin = GPIO_PIN_0|GPIO_PIN_10|GPIO_PIN_11|GPIO_PIN_12
                          |GPIO_PIN_13;
  GPIO_InitStruct.Mode = GPIO_MODE_OUTPUT_PP;
  GPIO_InitStruct.Pull = GPIO_NOPULL;
  GPIO_InitStruct.Speed = GPIO_SPEED_FREQ_LOW;
  HAL_GPIO_Init(GPIOG, &GPIO_InitStruct);

  /*Configure GPIO pin : PE7 */
  GPIO_InitStruct.Pin = GPIO_PIN_7;
  GPIO_InitStruct.Mode = GPIO_MODE_OUTPUT_PP;
  GPIO_InitStruct.Pull = GPIO_NOPULL;
  GPIO_InitStruct.Speed = GPIO_SPEED_FREQ_LOW;
  HAL_GPIO_Init(GPIOE, &GPIO_InitStruct);

  /*Configure GPIO pin : PA15 */
  GPIO_InitStruct.Pin = GPIO_PIN_15;
  GPIO_InitStruct.Mode = GPIO_MODE_OUTPUT_PP;
  GPIO_InitStruct.Pull = GPIO_NOPULL;
  GPIO_InitStruct.Speed = GPIO_SPEED_FREQ_LOW;
  HAL_GPIO_Init(GPIOA, &GPIO_InitStruct);

  /*Configure GPIO pins : PD0 PD1 PD2 PD3 */
  GPIO_InitStruct.Pin = GPIO_PIN_0|GPIO_PIN_1|GPIO_PIN_2|GPIO_PIN_3;
  GPIO_InitStruct.Mode = GPIO_MODE_OUTPUT_PP;
  GPIO_InitStruct.Pull = GPIO_NOPULL;
  GPIO_InitStruct.Speed = GPIO_SPEED_FREQ_LOW;
  HAL_GPIO_Init(GPIOD, &GPIO_InitStruct);

}

void Error_Handler(void)
{
  __disable_irq();
  while (1)
  {
  }
}
